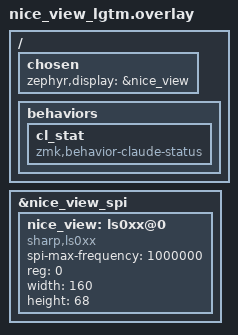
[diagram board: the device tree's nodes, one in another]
/*
 * Copyright (c) 2022 The ZMK Contributors
 *
 * SPDX-License-Identifier: MIT
 */

&nice_view_spi {
    status = "okay";
    nice_view: ls0xx@0 {
        compatible = "sharp,ls0xx";
        spi-max-frequency = <1000000>;
        reg = <0>;
        width = <160>;
        height = <68>;
    };
};

/ {
    chosen {
        zephyr,display = &nice_view;
    };
};

/ {
    behaviors {
        /* Claude Code status, invoked by claude/claude_relay.c on the central.
         * The node name is the split protocol device name: keep it <= 8 chars. */
        cl_stat: cl_stat {
            compatible = "zmk,behavior-claude-status";
            #binding-cells = <1>;
        };
    };
};
